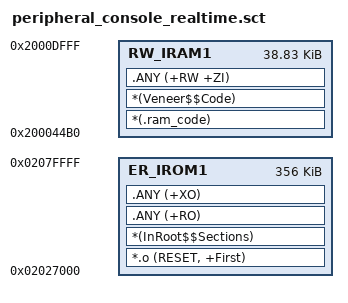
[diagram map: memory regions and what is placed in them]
; *************************************************************
; *** Scatter-Loading Description File generated by uVision ***
; *************************************************************

LR_IROM1 0x02027000 0x00059000  {    ; load region size_region
  ER_IROM1 0x02027000 0x00059000  {  ; load address = execution address
   *.o (RESET, +First)
   *(InRoot$$Sections)
   .ANY (+RO)
   .ANY (+XO)
  }
RW_IRAM1 0x200044B0 0x00009B50 {  ; RW data
   *(.ram_code)
   *(Veneer$$Code)
   .ANY (+RW +ZI)
  }
}

